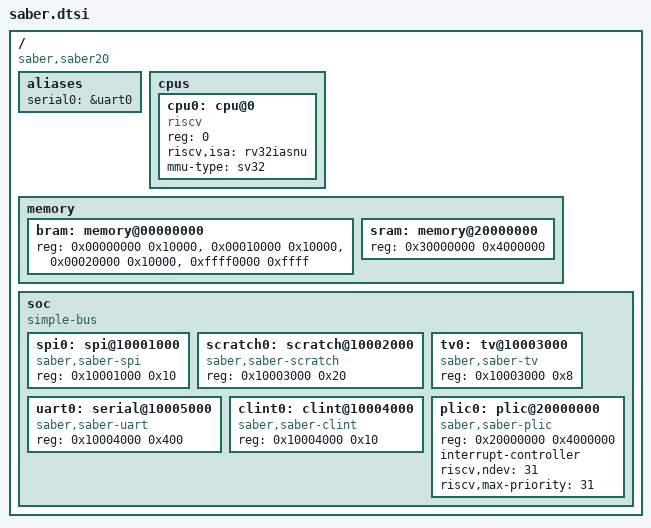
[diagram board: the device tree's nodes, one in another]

/ {
	#address-cells = <1>;
	#size-cells = <1>;
	compatible = "saber,saber20";

	aliases {
		serial0 = &uart0;
	};

    cpus {
        #address-cells = <1>;
        #size-cells = <0>;

        cpu0: cpu@0 {
			device_type = "cpu";
			reg = <0>;
			compatible = "riscv";
			riscv,isa = "rv32iasnu";
			mmu-type = "sv32";
		};
    };
    
    memory {
        #address-cells = <1>;
        #size-cells = <1>;

        bram: memory@00000000 {
            device_type = "memory";
            reg = <0x00000000 0x10000>,
                  <0x00010000 0x10000>,
                  <0x00020000 0x10000>,
                  <0xffff0000 0xffff>;
            reg-names = "bram0, bram1, bram2, bramStk";
        };

        sram: memory@20000000 {
            device_type = "memory";
            reg = <0x30000000 0x4000000>;
            reg-names = "sram0";
        };
    };

    soc {
        #address-cells = <1>;
        #size-cells = <1>;
        compatible = "simple-bus";

        spi0: spi@10001000 {
            compatible = "saber,saber-spi";
			reg = <0x10001000 0x10>;
        };

        scratch0: scratch@10002000 {
            compatible = "saber,saber-scratch";
			reg = <0x10003000 0x20>;
        };

        tv0: tv@10003000 {
            compatible = "saber,saber-tv";
			reg = <0x10003000 0x8>;
        };

        uart0: serial@10005000 {
			compatible = "saber,saber-uart";
			reg = <0x10004000 0x400>;
		};

        clint0: clint@10004000 {
            #interrupt-cells = <1>;
			compatible = "saber,saber-clint", "riscv,clint0";
			reg = <0x10004000 0x10>;
        };

        plic0: plic@20000000 {
            #interrupt-cells = <1>;
			compatible = "saber,saber-plic", "riscv,plic0";
			reg = <0x20000000 0x4000000>;
			interrupt-controller;
			riscv,ndev = <31>;
			riscv,max-priority = <31>;
        };
        
    };

};
